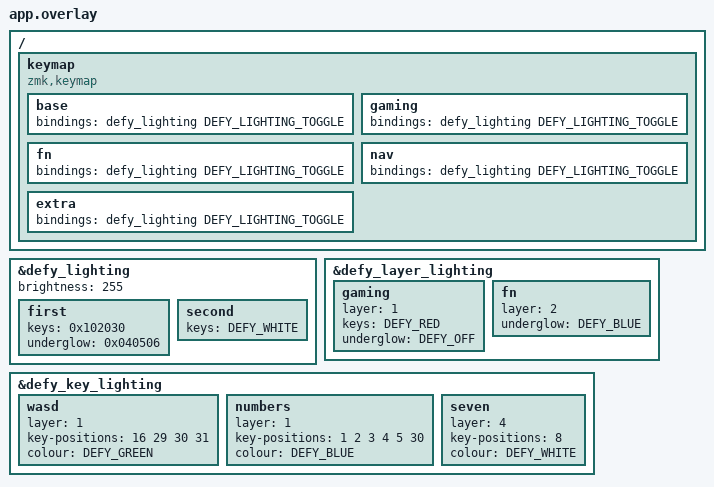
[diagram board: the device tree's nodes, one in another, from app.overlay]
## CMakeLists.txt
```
# SPDX-License-Identifier: MIT

cmake_minimum_required(VERSION 3.20.0)
include(${CMAKE_CURRENT_SOURCE_DIR}/../common/defy_test.cmake)
# app.overlay's behavior nodes and keymap take their bindings from ZMK.
list(APPEND DTS_ROOT ${DEFY_ZMK_APP})
find_package(Zephyr REQUIRED HINTS $ENV{ZEPHYR_BASE})
project(defy_lighting_test)

# Listeners run in link order: consumer.c after the lighting, which main.c includes.
target_sources(app PRIVATE src/main.c src/consumer.c
                           ${DEFY_ROOT}/lighting/defy_lighting_protocol.c
                           ${DEFY_ROOT}/drivers/split/defy_wired_protocol.c)
target_include_directories(app PRIVATE ${DEFY_ROOT}/tests/drivers/common)
# The looks and layer colours come from app.overlay; main.c fakes the dock.
target_compile_definitions(app PRIVATE CONFIG_DEFY_HALF_LEDS=1 CONFIG_DEFY_NEURON_DOCK=1)
defy_test_zmk_events(position_state_changed.c layer_state_changed.c)
```

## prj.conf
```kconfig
# SPDX-License-Identifier: MIT

CONFIG_ZTEST=y
CONFIG_LOG=y
CONFIG_CRC=y
```

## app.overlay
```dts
/* SPDX-License-Identifier: MIT */

/*
 * The module's behaviors, with two looks at full brightness, so that colours
 * reach the state unscaled, layer colours for two of five layers, and key
 * colours on the gaming layer and on the fifth, which has no layer colours.
 * The board's transform maps the key positions.
 */
#include <behaviors/defy.dtsi>
#include <dt-bindings/dygma/defy_lighting.h>
#include <dt-bindings/zmk/matrix_transform.h>

#include "../../../boards/dygma/defy/defy-transform.dtsi"

/ {
    keymap {
        compatible = "zmk,keymap";
        base { bindings = <&defy_lighting DEFY_LIGHTING_TOGGLE>; };
        gaming { bindings = <&defy_lighting DEFY_LIGHTING_TOGGLE>; };
        fn { bindings = <&defy_lighting DEFY_LIGHTING_TOGGLE>; };
        nav { bindings = <&defy_lighting DEFY_LIGHTING_TOGGLE>; };
        extra { bindings = <&defy_lighting DEFY_LIGHTING_TOGGLE>; };
    };
};

&defy_lighting {
    brightness = <255>;
    first { keys = <0x102030>; underglow = <0x040506>; };
    second { keys = <DEFY_WHITE>; };
};

&defy_layer_lighting {
    gaming { layer = <1>; keys = <DEFY_RED>; underglow = <DEFY_OFF>; };
    fn { layer = <2>; underglow = <DEFY_BLUE>; };
};

&defy_key_lighting {
    wasd { layer = <1>; key-positions = <16 29 30 31>; colour = <DEFY_GREEN>; };
    numbers { layer = <1>; key-positions = <1 2 3 4 5 30>; colour = <DEFY_BLUE>; };
    seven { layer = <4>; key-positions = <8>; colour = <DEFY_WHITE>; };
};
```

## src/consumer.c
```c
/* SPDX-License-Identifier: MIT */

#include <zmk/events/position_state_changed.h>

int consume_position(const zmk_event_t *event);

/* Its own source, linked after main.c, as ZMK's listeners link after the module's. */
ZMK_LISTENER(lighting_test_consumer, consume_position);
ZMK_SUBSCRIPTION(lighting_test_consumer, zmk_position_state_changed);
```
